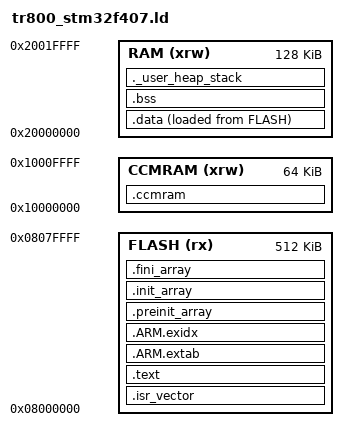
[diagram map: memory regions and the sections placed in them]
ENTRY(Reset_Handler)

_Min_Heap_Size = 0x1000;
_Min_Stack_Size = 0x2000;

MEMORY
{
  FLASH (rx)      : ORIGIN = 0x08000000, LENGTH = 512K
  RAM (xrw)       : ORIGIN = 0x20000000, LENGTH = 128K
  CCMRAM (xrw)    : ORIGIN = 0x10000000, LENGTH = 64K
}

SECTIONS
{
  .isr_vector :
  {
    . = ALIGN(4);
    KEEP(*(.isr_vector))
    . = ALIGN(4);
  } > FLASH

  .text :
  {
    . = ALIGN(4);
    *(.text*)
    *(.rodata*)
    *(.glue_7)
    *(.glue_7t)
    . = ALIGN(4);
    _etext = .;
  } > FLASH

  .ARM.extab : { *(.ARM.extab* .gnu.linkonce.armextab.*) } > FLASH
  .ARM.exidx : { *(.ARM.exidx* .gnu.linkonce.armexidx.*) } > FLASH

  .preinit_array :
  {
    PROVIDE_HIDDEN(__preinit_array_start = .);
    KEEP(*(.preinit_array*))
    PROVIDE_HIDDEN(__preinit_array_end = .);
  } > FLASH

  .init_array :
  {
    PROVIDE_HIDDEN(__init_array_start = .);
    KEEP(*(SORT(.init_array.*)))
    KEEP(*(.init_array*))
    PROVIDE_HIDDEN(__init_array_end = .);
  } > FLASH

  .fini_array :
  {
    PROVIDE_HIDDEN(__fini_array_start = .);
    KEEP(*(SORT(.fini_array.*)))
    KEEP(*(.fini_array*))
    PROVIDE_HIDDEN(__fini_array_end = .);
  } > FLASH

  .data :
  {
    . = ALIGN(4);
    _sdata = .;
    *(.data*)
    . = ALIGN(4);
    _edata = .;
  } > RAM AT > FLASH

  _sidata = LOADADDR(.data);

  .bss (NOLOAD) :
  {
    . = ALIGN(4);
    _sbss = .;
    *(.bss*)
    *(COMMON)
    . = ALIGN(4);
    _ebss = .;
  } > RAM

  .ccmram (NOLOAD) :
  {
    . = ALIGN(4);
    *(.ccmram*)
    . = ALIGN(4);
  } > CCMRAM

  ._user_heap_stack (NOLOAD) :
  {
    . = ALIGN(8);
    PROVIDE(end = .);
    PROVIDE(_end = .);
    . = . + _Min_Heap_Size;
    . = . + _Min_Stack_Size;
    . = ALIGN(8);
  } > RAM

  /DISCARD/ :
  {
    *(.note*)
    *(.comment*)
  }
}

PROVIDE(_estack = ORIGIN(RAM) + LENGTH(RAM));
